# RX64M_SCI_Pilot register map
File version: 1.0
RX64M_SCI_Pilot peripheral registers generated from iodefine.h (pilot).
Registers are 8-bit, read-write, reset 0x0 unless marked. A register's access mark holds for its fields unless they carry their own. Offsets are from the block's base; lines under a group give offsets from that group; [hi:lo] are bit positions; {n}, {i} and the like mark numbered series; 'fields as' and 'values as' point back to an identical list; <NAME> marks a mode.

## Memory map
{0x8A000+0x20*n} SCI{n} size 0x13 (n=0..7)
{0x8A000+0x20*n} SMCI{n} size 0x7 (n=0..7)
0x0008B300 SCI12 size 0x34
0x0008B300 SMCI12 size 0x7

## SCI0
Base 0x0008A000
Same registers: SCI1 0x0008A020, SCI2 0x0008A040, SCI3 0x0008A060, SCI4 0x0008A080, SCI5 0x0008A0A0, SCI6 0x0008A0C0, SCI7 0x0008A0E0
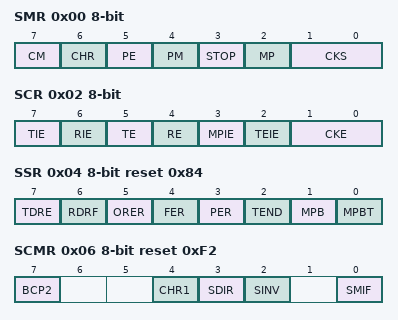
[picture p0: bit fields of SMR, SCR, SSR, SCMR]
0x00 SMR
  [7] CM, [6] CHR, [5] PE, [4] PM, [3] STOP, [2] MP, [1:0] CKS
0x01 BRR reset 0xFF
0x02 SCR
  [7] TIE, [6] RIE, [5] TE, [4] RE, [3] MPIE, [2] TEIE, [1:0] CKE
0x03 TDR reset 0xFF
0x04 SSR reset 0x84
  [7] TDRE, [6] RDRF, [5] ORER, [4] FER, [3] PER, [2] TEND, [1] MPB, [0] MPBT
0x05 RDR ro
0x06 SCMR reset 0xF2
  [7] BCP2, [4] CHR1, [3] SDIR, [2] SINV, [0] SMIF
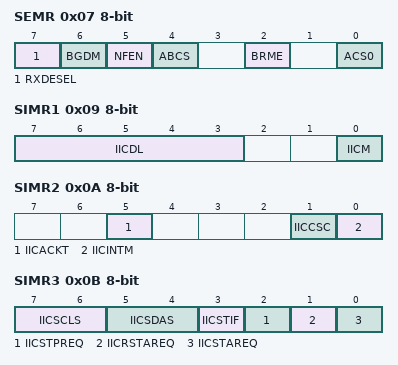
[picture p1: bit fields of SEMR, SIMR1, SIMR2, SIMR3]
0x07 SEMR
  [7] RXDESEL, [6] BGDM, [5] NFEN, [4] ABCS, [2] BRME, [0] ACS0
0x08 SNFR
  [2:0] NFCS
0x09 SIMR1
  [7:3] IICDL, [0] IICM
0x0A SIMR2
  [5] IICACKT, [1] IICCSC, [0] IICINTM
0x0B SIMR3
  [7:6] IICSCLS, [5:4] IICSDAS, [3] IICSTIF, [2] IICSTPREQ, [1] IICRSTAREQ, [0] IICSTAREQ
0x0C SISR
  [0] IICACKR
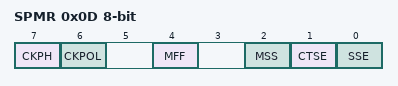
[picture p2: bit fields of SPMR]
0x0D SPMR
  [7] CKPH, [6] CKPOL, [4] MFF, [2] MSS, [1] CTSE, [0] SSE
0x0E TDRHL 16-bit reset 0xFFFF
0x10 RDRHL 16-bit ro
0x12 MDDR reset 0xFF

## SCI12
Base 0x0008B300
Registers as SCI0; these are added or differ:
0x20 ESMER
  [0] ESME
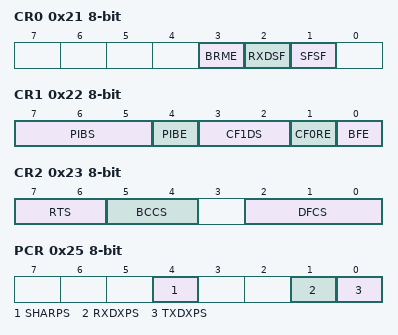
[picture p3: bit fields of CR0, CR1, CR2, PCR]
0x21 CR0
  [3] BRME, [2] RXDSF, [1] SFSF
0x22 CR1
  [7:5] PIBS, [4] PIBE, [3:2] CF1DS, [1] CF0RE, [0] BFE
0x23 CR2
  [7:6] RTS, [5:4] BCCS, [2:0] DFCS
0x24 CR3
  [0] SDST
0x25 PCR
  [4] SHARPS, [1] RXDXPS, [0] TXDXPS
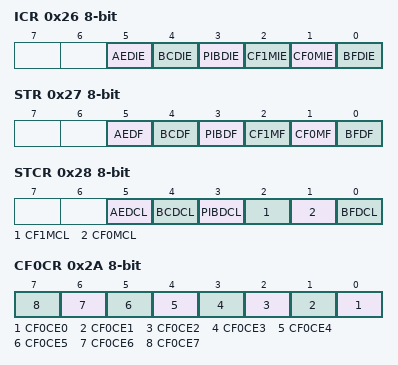
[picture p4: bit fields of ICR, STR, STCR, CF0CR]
0x26 ICR
  [5] AEDIE, [4] BCDIE, [3] PIBDIE, [2] CF1MIE, [1] CF0MIE, [0] BFDIE
0x27 STR ro
  [5] AEDF, [4] BCDF, [3] PIBDF, [2] CF1MF, [1] CF0MF, [0] BFDF
0x28 STCR
  [5] AEDCL, [4] BCDCL, [3] PIBDCL, [2] CF1MCL, [1] CF0MCL, [0] BFDCL
0x29 CF0DR
0x2A CF0CR
  [n] CF0CE{n} (n=0..7)
0x2B CF0RR ro
0x2C PCF1DR
0x2D SCF1DR
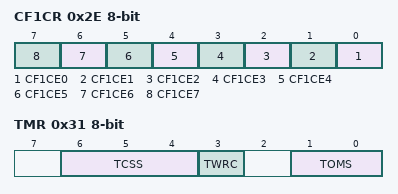
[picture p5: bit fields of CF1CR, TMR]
0x2E CF1CR
  [n] CF1CE{n} (n=0..7)
0x2F CF1RR ro
0x30 TCR
  [0] TCST
0x31 TMR
  [6:4] TCSS, [3] TWRC, [1:0] TOMS
0x32 TPRE reset 0xFF
0x33 TCNT reset 0xFF

## SMCI0
Base 0x0008A000; alternate view of SCI0
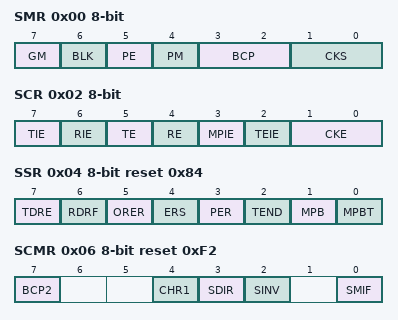
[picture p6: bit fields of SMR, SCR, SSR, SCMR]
0x00 SMR
  [7] GM, [6] BLK, [5] PE, [4] PM, [3:2] BCP, [1:0] CKS
0x01 BRR reset 0xFF
0x02 SCR
  [7] TIE, [6] RIE, [5] TE, [4] RE, [3] MPIE, [2] TEIE, [1:0] CKE
0x03 TDR reset 0xFF
0x04 SSR reset 0x84
  [7] TDRE, [6] RDRF, [5] ORER, [4] ERS, [3] PER, [2] TEND, [1] MPB, [0] MPBT
0x05 RDR ro
0x06 SCMR reset 0xF2
  [7] BCP2, [4] CHR1, [3] SDIR, [2] SINV, [0] SMIF

## SMCI1
Base 0x0008A020; alternate view of SCI1
Registers as SMCI0.

## SMCI2
Base 0x0008A040; alternate view of SCI2
Registers as SMCI0.

## SMCI3
Base 0x0008A060; alternate view of SCI3
Registers as SMCI0.

## SMCI4
Base 0x0008A080; alternate view of SCI4
Registers as SMCI0.

## SMCI5
Base 0x0008A0A0; alternate view of SCI5
Registers as SMCI0.

## SMCI6
Base 0x0008A0C0; alternate view of SCI6
Registers as SMCI0.

## SMCI7
Base 0x0008A0E0; alternate view of SCI7
Registers as SMCI0.

## SMCI12
Base 0x0008B300; alternate view of SCI12
Registers as SMCI0.
